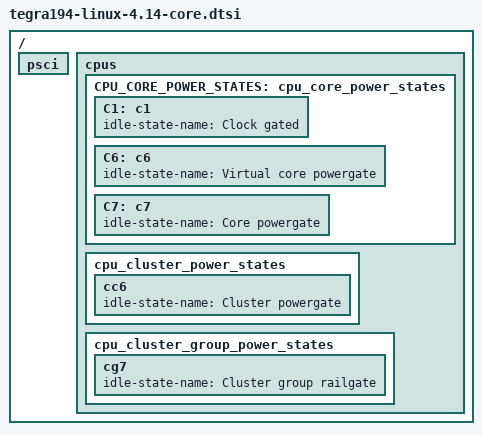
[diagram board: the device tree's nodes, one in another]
/*
 * Copyright (c) 2018-2020, NVIDIA CORPORATION.  All rights reserved.
 *
 * This program is free software; you can redistribute it and/or modify it
 * under the terms and conditions of the GNU General Public License,
 * version 2, as published by the Free Software Foundation.
 *
 * This program is distributed in the hope it will be useful, but WITHOUT
 * ANY WARRANTY; without even the implied warranty of MERCHANTABILITY or
 * FITNESS FOR A PARTICULAR PURPOSE.  See the GNU General Public License for
 * more details.
 *
 * You should have received a copy of the GNU General Public License
 * along with this program.  If not, see <http://www.gnu.org/licenses/>.
 */

/*
 * tegra194-linux-4.14-core.dtsi
 */

/ {

	psci {
		status = "okay";
	};

	cpus {
		CPU_CORE_POWER_STATES: cpu_core_power_states {
			C1: c1 {
				idle-state-name = "Clock gated";
			};

			C6: c6 {
				idle-state-name = "Virtual core powergate";
			};

			C7: c7 {
				idle-state-name = "Core powergate";
			};
		};

		cpu_cluster_power_states {
			cc6 {
				idle-state-name = "Cluster powergate";
			};
		};

		cpu_cluster_group_power_states {
			cg7 {
				idle-state-name = "Cluster group railgate";
			};
		};
	};

};
